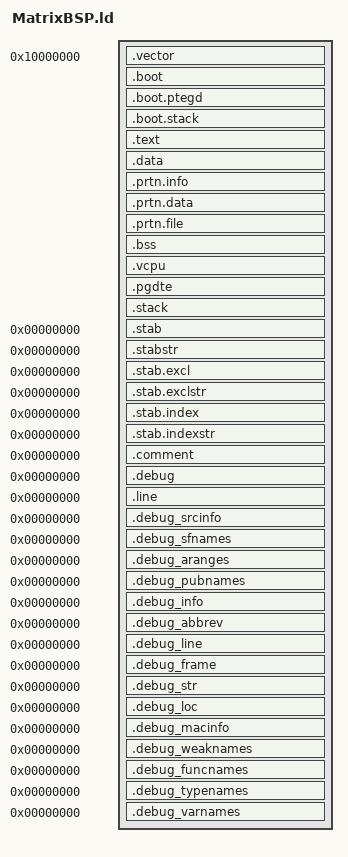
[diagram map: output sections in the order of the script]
/*********************************************************************************************************
**
**                                    中国软件开源组织
**
**                                   嵌入式实时操作系统
**
**                                       SylixOS(TM)
**
**                               Copyright  All Rights Reserved
**
**--------------文件信息--------------------------------------------------------------------------------
**
** 文   件   名: SylixOSBSP.ld
**
** 创   建   人: Han.hui (韩辉)
**
** 文件创建日期: 2009-01-04
**
** 描        述: bspimx6 链接脚本文件
*********************************************************************************************************/

/*********************************************************************************************************
    包含配置文件
*********************************************************************************************************/

/* INCLUDE "config.lds" */
/*
MEMORY
{
  TEXT (rx) : ORIGIN = (0x10000000), LENGTH = (6 * 1024 * 1024)
  DATA (rw) : ORIGIN = (0x10000000) + ((6 * 1024 * 1024)), LENGTH = (64 * 1024 * 1024)
}
*/
/*
MEMORY
{
  RAM (rwx) : ORIGIN = (0x10000000), LENGTH = (1 * 1024 * 1024 * 1024)
}
*/
BOOT_PGD_TABLE_SIZE  = (4 * 4096);
BOOT_PTE_TABLE_SIZE  = ((247+32+512) * 4 * 256);                        /*  791 张二级页表              */
BOOT_STACK_SIZE      = (16 * 1024);
KERN_STACK_SIZE      = (4 * 128 * 1024);

/*********************************************************************************************************
    链接配置
*********************************************************************************************************/

OUTPUT_FORMAT(elf32-littlearm)                                          /*  binary file format          */
OUTPUT_ARCH(ARM)                                                        /*  target select               */
ENTRY(boot)

/*********************************************************************************************************
    段定义
*********************************************************************************************************/

SECTIONS
{
    /******************************************
      MMU 未开启时运行的代码
    ******************************************/
    /*. = ORIGIN(RAM);*/
    . = 0x10000000;

    /******************************************
      异常向量表
    ******************************************/
    .vector : {
        *(.vector)                                                      /*  异常向量表                  */
    }

    /******************************************
      初始化代码
    ******************************************/
    .boot ALIGN(8): {
        *(.boot.text)                                                   /*  设置初始页表的代码          */
        *(.boot.data)
    }

    /******************************************
      初始化时使用的页表
    ******************************************/
    . = ALIGN(0x1000);                                                  /*  4K 对齐, 为 boot 代码留 4K  */
    .boot.ptegd (NOLOAD) : {
        . = ALIGN(0x400);                                               /*  1K 对齐                     */
        PROVIDE (_pte_table = .);                                       /*  二级页表                    */
        . += BOOT_PTE_TABLE_SIZE;
        
        . = ALIGN(0x4000);                                              /*  16K 对齐                    */
        PROVIDE (_pgd_table = .);                                       /*  一级页表                    */
        . += BOOT_PGD_TABLE_SIZE;
    }
    /******************************************
      初始化时使用的堆栈
    ******************************************/
    .boot.stack (NOLOAD) : {
        . = ALIGN(0x400);
        . += BOOT_STACK_SIZE;
        PROVIDE (_boot_stack_end = .);                                  /*  初始化时使用堆栈            */
    }

    
/*********************************************************************************************************
    Matrix 微内核核心代码, 运行在最高 1G 地址处 0xC0000000
*********************************************************************************************************/
    . = ALIGN(0x1000);
    PROVIDE (__mx_phys_addr = .);                                       /*  微内核代码所在的物理地址    */
    . = . + 0xB0000000;
    PROVIDE (__mx_virt_addr = .);                                       /*  微内核代码运行的虚拟地址    */

/*********************************************************************************************************
    代码段  LMA == __mx_virt_addr, VMA == __mx_phys_addr
*********************************************************************************************************/

    .text : AT(ADDR(.text) - __mx_virt_addr + __mx_phys_addr) {
        . = ALIGN(4);
        PROVIDE (_text = .);

        *(.text)
        *(.text.*)                                                      /*  cpp namespace function      */
        *(.romrun)                                                      /*  ROM 中必须的函数            */
        *(.rodata)                                                      /*  read-only data (constants)  */
        *(.rodata*)
        *(.glue_7)
        *(.glue_7t)

        . = ALIGN(0x100);
        . = ALIGN(4);
        PROVIDE (_etext = .);
    }
    

/*********************************************************************************************************
    数据段  带有初始化值的全局变量放在这里
*********************************************************************************************************/

    .data : AT(ADDR(.data) - __mx_virt_addr + __mx_phys_addr) {
        PROVIDE (_data = .);
        
        *(.data)
         
        . = ALIGN(4);
        PROVIDE (_edata = .);
    }

/*********************************************************************************************************
    进程镜像段  进程镜像文件及信息放在这里
*********************************************************************************************************/

    .prtn.info : AT(ADDR(.prtn.info) - __mx_virt_addr + __mx_phys_addr) {
        . = ALIGN(4);
        PROVIDE (_prtn_info = .);
        
        *(.prtn.info)
         
        . = ALIGN(4);
        PROVIDE (_eprtn_info = .);
    }

    .prtn.data : AT(ADDR(.prtn.data) - __mx_virt_addr + __mx_phys_addr) {
        . = ALIGN(4);
        PROVIDE (_prtn_data = .);
        
        *(.prtn.data)
         
        . = ALIGN(4);
        PROVIDE (_eprtn_data = .);
    }

    .prtn.file : AT(ADDR(.prtn.file) - __mx_virt_addr + __mx_phys_addr) {
        . = ALIGN(4);
        PROVIDE (_prtn_file = .);
        
        *(.prtn.file)
         
        . = ALIGN(4);
        PROVIDE (_eprtn_file = .);
    }

/*********************************************************************************************************
    清零段

    NOLOAD 表示不装载, 启动程序只需要借助 __bss_start 和 __bss_end 两个符号指定的起始地址和结束地址
    将 .bss 区域清零即可. (注意 *.noinit 可以不进行清零)
*********************************************************************************************************/

    .bss (NOLOAD) : {
        . = ALIGN(4);
        *(.noinit)
        
        . = ALIGN(4);
        PROVIDE (__bss_start = .);
        
        *(.bss)
        
        . = ALIGN(4);
        *(COMMON)
    }

/*********************************************************************************************************
     VCPU 控制块段    Matrix 线程控制块和内核堆栈
*********************************************************************************************************/
    . = ALIGN(0x4000);
    .vcpu (NOLOAD) : {
        . = ALIGN(0x1000);                                              /*  4K 对齐                    */
        *(.vcpu_kstack)

        . = ALIGN(4);
        PROVIDE (__bss_end = .);
    }
/*********************************************************************************************************
     页表段    Matrix 内核和分区映射使用到的页表
*********************************************************************************************************/
    . = ALIGN(0x4000);
    .pgdte (NOLOAD) : {
        . = ALIGN(0x4000);                                              /*  16K 对齐                    */
        *(.pgd_table)

        . = ALIGN(0x400);                                               /*  1K 对齐                    */
        *(.pte_table)
    }
/*********************************************************************************************************
     栈段    Matrix 进入高地址时使用, 异常入口也使用
*********************************************************************************************************/
    . = ALIGN(8);
    .stack (NOLOAD) : {
        . = ALIGN(8);
        PROVIDE (__stack_start = .);
        
        . += KERN_STACK_SIZE;
        
        . = ALIGN(8);
        PROVIDE (__stack_end = .);
    }

/*********************************************************************************************************
    Stabs debugging sections
*********************************************************************************************************/

    .stab               0 : {*(.stab) }
    .stabstr            0 : {*(.stabstr) }
    .stab.excl          0 : {*(.stab.excl) }
    .stab.exclstr       0 : {*(.stab.exclstr) }
    .stab.index         0 : {*(.stab.index) }
    .stab.indexstr      0 : {*(.stab.indexstr) }
    .comment            0 : {*(.comment) }

/*********************************************************************************************************
    Symbols in the DWARF debugging sections are relative to the beginning
    of the section so we begin them at 0.
*********************************************************************************************************/

/*********************************************************************************************************
    DWARF 1
*********************************************************************************************************/

    .debug              0 : {*(.debug) }
    .line               0 : {*(.line) }

/*********************************************************************************************************
    GNU DWARF 1 extensions
*********************************************************************************************************/

    .debug_srcinfo      0 : {*(.debug_srcinfo) }
    .debug_sfnames      0 : {*(.debug_sfnames) }

/*********************************************************************************************************
    DWARF 1.1 and DWARF 2
*********************************************************************************************************/

    .debug_aranges      0 : {*(.debug_aranges) }
    .debug_pubnames     0 : {*(.debug_pubnames) }

/*********************************************************************************************************
    DWARF 2
*********************************************************************************************************/

    .debug_info         0 : {*(.debug_info .gnu.linkonce.wi.*) }
    .debug_abbrev       0 : {*(.debug_abbrev) }
    .debug_line         0 : {*(.debug_line) }
    .debug_frame        0 : {*(.debug_frame) }
    .debug_str          0 : {*(.debug_str) }
    .debug_loc          0 : {*(.debug_loc) }
    .debug_macinfo      0 : {*(.debug_macinfo) }

/*********************************************************************************************************
    SGI/MIPS DWARF 2 extensions
*********************************************************************************************************/

    .debug_weaknames    0 : {*(.debug_weaknames) }
    .debug_funcnames    0 : {*(.debug_funcnames) }
    .debug_typenames    0 : {*(.debug_typenames) }
    .debug_varnames     0 : {*(.debug_varnames) }
}

/*********************************************************************************************************
  END
*********************************************************************************************************/

